# MKE18F16 register map
Vendor: Freescale Semiconductor, Inc.; Series: Kinetis_E; File version: 1.6
CPU: CM4 r0p1, little endian, no MPU, FPU, VTOR, 4 interrupt priority bits
Registers are 32-bit, read-write, reset 0x0 unless marked. A register's access mark holds for its fields unless they carry their own. Offsets are from the block's base; [hi:lo] are bit positions; {n}, {i} and the like mark numbered series; 'fields as' and 'values as' point back to an identical list.

## CMP0 — High-Speed Comparator (CMP), Voltage Reference (VREF) Digital-to-Analog Converter (DAC), and Analog Mux (ANMUX)
Base 0x40073000; register names take the prefix CMP0_
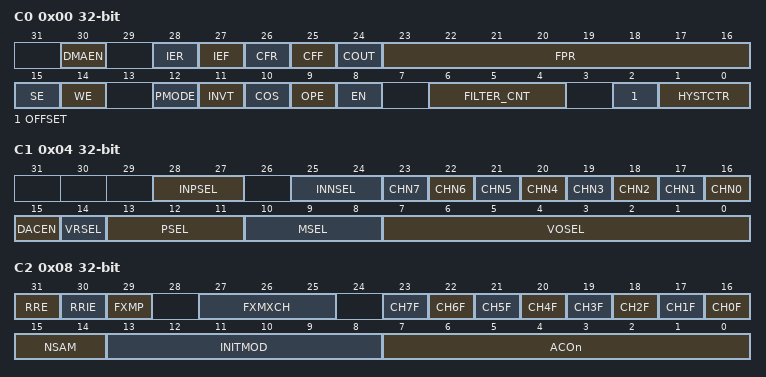
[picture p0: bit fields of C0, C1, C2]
0x00 C0 — CMP Control Register 0
  [30] DMAEN — DMA Enable
    0=DMA is disabled; 1=DMA is enabled
  [28] IER — Comparator Interrupt Enable Rising
    0=Interrupt is disabled; 1=Interrupt is enabled
  [27] IEF — Comparator Interrupt Enable Falling
    0=Interrupt is disabled; 1=Interrupt is enabled
  [26] CFR — Analog Comparator Flag Rising
    0=A rising edge has not been detected on COUT; 1=A rising edge on COUT has occurred
  [25] CFF — Analog Comparator Flag Falling
    0=A falling edge has not been detected on COUT; 1=A falling edge on COUT has occurred
  [24] COUT ro — Analog Comparator Output
  [23:16] FPR — Filter Sample Period
  [15] SE — Sample Enable
    0=Sampling mode is not selected; 1=Sampling mode is selected
  [14] WE — Windowing Enable
    0=Windowing mode is not selected; 1=Windowing mode is selected
  [12] PMODE — Power Mode Select
    0=Low Speed (LS) comparison mode is selected; 1=High Speed (HS) comparison mode is selected, in VLPx mode, or Stop mode switched to Low Speed (LS) mode
  [11] INVT — Comparator invert
    0=Does not invert the comparator output; 1=Inverts the comparator output
  [10] COS — Comparator Output Select
    0=Set CMPO to equal COUT (filtered comparator output); 1=Set CMPO to equal COUTA (unfiltered comparator output)
  [9] OPE — Comparator Output Pin Enable
    0=When OPE is 0, the comparator output (after window/filter settings dependent on software configuration) is not available to a packaged pin; 1=When OPE is 1, and if the software has configured the comparator to own a packaged pin, the comparator is available in a packaged pin
  [8] EN — Comparator Module Enable
    0=Analog Comparator is disabled; 1=Analog Comparator is enabled
  [6:4] FILTER_CNT — Filter Sample Count
    0=Filter is disabled. If SE = 1, then COUT is a logic zero (this is not a legal state, and is not recommended). If SE = 0, COUT = COUTA.; 1=1 consecutive sample must agree (comparator output is simply sampled); {v}={v} consecutive samples must agree (v=2..7)
  [2] OFFSET — Comparator hard block offset control. See chip data sheet to get the actual offset value with each level
    0=The comparator hard block output has level 0 offset internally; 1=The comparator hard block output has level 1 offset internally
  [1:0] HYSTCTR — Comparator hard block hysteresis control. See chip data sheet to get the actual hystersis value with each level
    {v}=The hard block output has level {v} hysteresis internally (v=0..3)
0x04 C1 — CMP Control Register 1
  [28:27] INPSEL — Selection of the input to the positive port of the comparator
    0=IN0, from the 8-bit DAC output; 1=IN1, from the analog 8-1 mux
  [25:24] INNSEL — Selection of the input to the negative port of the comparator
    values as INPSEL
  [n+16] CHN{n} (n=0..7) — Channel {n} input enable
  [15] DACEN — DAC Enable
    0=DAC is disabled; 1=DAC is enabled
  [14] VRSEL — Supply Voltage Reference Source Select
    0=Vin1 is selected as resistor ladder network supply reference Vin; 1=Vin2 is selected as resistor ladder network supply reference Vin
  [13:11] PSEL — Plus Input MUX Control
    {v}=IN{v} (v=0..7)
  [10:8] MSEL — Minus Input MUX Control
    {v}=IN{v} (v=0..7)
  [7:0] VOSEL — DAC Output Voltage Select
0x08 C2 — CMP Control Register 2
  [31] RRE — Round-Robin Enable
    0=Round-robin operation is disabled; 1=Round-robin operation is enabled
  [30] RRIE — Round-Robin interrupt enable
    0=The round-robin interrupt is disabled; 1=The round-robin interrupt is enabled when a comparison result changes from the last sample
  [29] FXMP — Fixed MUX Port
    0=The Plus port is fixed. Only the inputs to the Minus port are swept in each round.; 1=The Minus port is fixed. Only the inputs to the Plus port are swept in each round.
  [27:25] FXMXCH — Fixed channel selection
    {v}=Channel {v} is selected as the fixed reference input for the fixed mux port (v=0..7)
  [n+16] CH{n}F (n=0..7) — Channel {n} input changed flag
  [15:14] NSAM — Number of sample clocks
    0=The comparison result is sampled as soon as the active channel is scanned in one round-robin clock; 1=The sampling takes place 1 round-robin clock cycle after the next cycle of the round-robin clock; 2=The sampling takes place 2 round-robin clock cycles after the next cycle of the round-robin clock; 3=The sampling takes place 3 round-robin clock cycles after the next cycle of the round-robin clock
  [13:8] INITMOD — Comparator and DAC initialization delay modulus.
    0=The modulus is set to 64(same with 111111)
  [7:0] ACOn — The result of the input comparison for channel n

## CMP1 — High-Speed Comparator (CMP), Voltage Reference (VREF) Digital-to-Analog Converter (DAC), and Analog Mux (ANMUX)
Base 0x40074000; register names take the prefix CMP1_
Registers as CMP0.

## CMP2 — High-Speed Comparator (CMP), Voltage Reference (VREF) Digital-to-Analog Converter (DAC), and Analog Mux (ANMUX)
Base 0x40075000; register names take the prefix CMP2_
Registers as CMP0.
